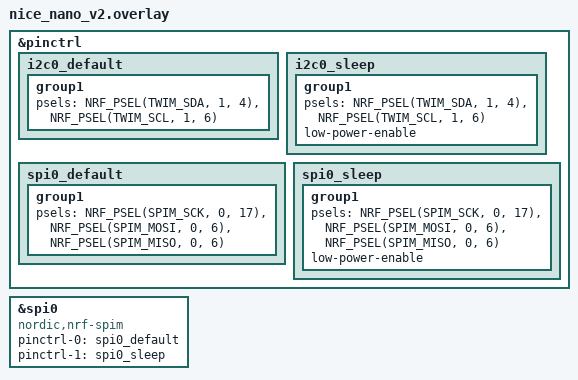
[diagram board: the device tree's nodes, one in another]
#include <dt-bindings/zmk/input_transform.h>

&pinctrl {
    i2c0_default: i2c0_default {
        group1 {
            psels = <NRF_PSEL(TWIM_SDA, 1, 4)>,
                <NRF_PSEL(TWIM_SCL, 1, 6)>;
        };
    };

    i2c0_sleep: i2c0_sleep {
        group1 {
            psels = <NRF_PSEL(TWIM_SDA, 1, 4)>,
                <NRF_PSEL(TWIM_SCL, 1, 6)>;
            low-power-enable;
        };
    }; 

    spi0_default: spi0_default {
        group1 {
            psels
              = <NRF_PSEL(SPIM_SCK, 0, 17)>
              , <NRF_PSEL(SPIM_MOSI, 0, 6)>
              , <NRF_PSEL(SPIM_MISO, 0, 6)>
              ;
        };
    };

    spi0_sleep: spi0_sleep {
        group1 {
            psels
              = <NRF_PSEL(SPIM_SCK, 0, 17)>
              , <NRF_PSEL(SPIM_MOSI, 0, 6)>
              , <NRF_PSEL(SPIM_MISO, 0, 6)>
              ;
            low-power-enable;
        };
    };
};
 
&spi0 {
  status = "okay";
  compatible = "nordic,nrf-spim";
  pinctrl-0 = <&spi0_default>;
  pinctrl-1 = <&spi0_sleep>;
  pinctrl-names = "default", "sleep";
};
